# MCAN0_CFG_MCAN0_CFG register map
Vendor: Texas Instruments
Peripheral module from a debugger description file (folder AM263).
Registers are 32-bit, read-write, reset 0x0 unless marked. A register's access mark holds for its fields unless they carry their own. Offsets are as the file gives them; lines under a group give offsets from that group; [hi:lo] are bit positions; {n}, {i} and the like mark numbered series; 'fields as' and 'values as' point back to an identical list; <NAME> marks a mode.

## MCAN0_CFG_MCAN0_CFG
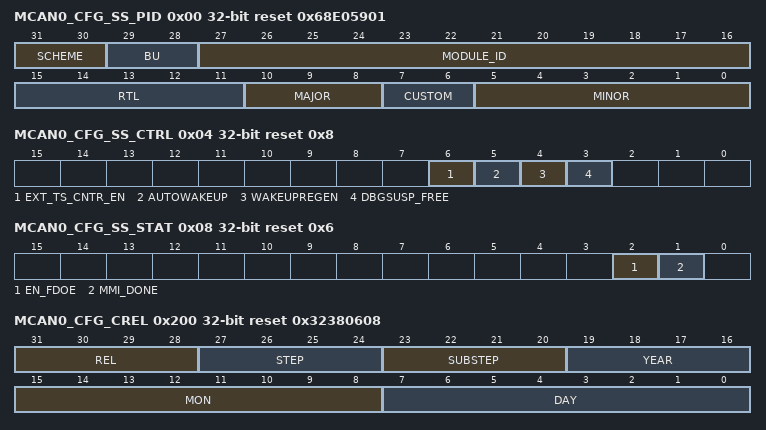
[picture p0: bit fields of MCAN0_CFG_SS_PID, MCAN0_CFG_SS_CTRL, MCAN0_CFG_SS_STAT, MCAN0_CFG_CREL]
0x00 MCAN0_CFG_SS_PID ro reset 0x68E05901
  [31:30] SCHEME — PID register scheme
  [29:28] BU — Business Unit: 10 = Processors
  [27:16] MODULE_ID
  [15:11] RTL — RTL revision. Will vary depending on release.
  [10:8] MAJOR — Major revision
  [7:6] CUSTOM
  [5:0] MINOR — Minor revision
0x04 MCAN0_CFG_SS_CTRL reset 0x8
  [6] EXT_TS_CNTR_EN — External TimeStamp Counter Enable
  [5] AUTOWAKEUP — Automatic Wakeup Enable
  [4] WAKEUPREGEN — Wakeup Request Enable
  [3] DBGSUSP_FREE — 0-Honor Debug Suspend, 1-Disregard debug suspend
0x08 MCAN0_CFG_SS_STAT ro reset 0x6
  [2] EN_FDOE — Reflects the value of mcanss_enable_fdoe configuration portx=mcanss_enable_fdoe
  [1] MMI_DONE — 0:Memory Initialization is in progress, 1:Memory Intialization Done
0x0C MCAN0_CFG_SS_ICS wo
  [0] ICS — This bit contains the External TimeStamp Counter Overflow Interrupt status. Write '1' to clear bits. (ICS - Interrupt Clear Shadow Register)
0x10 MCAN0_CFG_SS_IRS ro
  [0] IRS — External TimeStamp Counter Overflow Interrupt status. Read raw interrupt status. (IRS - Interrupt Raw Status Register)
0x14 MCAN0_CFG_SS_IECS wo
  [0] IECS — External TimeStamp Counter Overflow Interrupt. Write '1' to clear bits. (IECS - Interrupt Enable Clear Shadow Register)
0x18 MCAN0_CFG_SS_IE
  [0] IE — External TimeStamp Counter Overflow Interrupt. Write '1' to set interrupt enable. Read returns interrupt enable. (IE - Interrupt Enable Register)
0x1C MCAN0_CFG_SS_IES ro
  [0] IES — External TimeStamp Counter Overflow Interrupt. Read Enabled Interrupts. (IES - Interrupt Enable Status)
0x20 MCAN0_CFG_SS_EOI wo
  [7:0] EOI — Write with bit position of targeted interrupt. (E.g. Ext TS is bit 0).Upon write, level interrupt will clear and if unserviced interrupt counter > 1 will issue another pulse interrupt. Field values: ext_ts_eoi(0): EOI value for External TS interrupt mcan_0_eoi(1): EOI value for mcan[0] interrupt mcan_1_eoi(2): EOI value for mcan[1] interrupt(EOI - End Of Interrupt)
0x24 MCAN0_CFG_SS_EXT_TS_PS
  [23:0] PRESCALE — External Timestamp Prescaler reload value.External Timestamp count rate is host clock rate divided by this valuewith one exception: a value of 0 has the same effect as 1 .
0x28 MCAN0_CFG_SS_EXT_TS_USIC ro
  [4:0] EXT_TS_INTR_CNTR — Number of unserviced rollover interrupts. If >1 an EOI write will issue another pulse interrupt (EXT_TS_USIC - External TImeStamp Unserviced Interrupts Counter)
0x200 MCAN0_CFG_CREL ro reset 0x32380608
  [31:28] REL — Core Release
  [27:24] STEP — Step of Core Release
  [23:20] SUBSTEP — Sub-Step of Core Release
  [19:16] YEAR — Time Stamp Year
  [15:8] MON — Time Stamp Month
  [7:0] DAY — Time Stamp Day
0x204 MCAN0_CFG_ENDN ro reset 0x87654321
  [31:0] ETV — Endianess test value
0x208 MCAN0_CFG_CUST ro
  [31:0] CUST — Custom
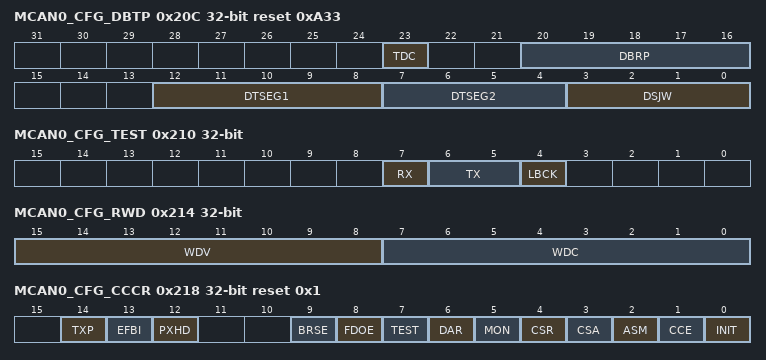
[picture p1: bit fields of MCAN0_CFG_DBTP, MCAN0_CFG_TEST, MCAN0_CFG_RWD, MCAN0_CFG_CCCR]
0x20C MCAN0_CFG_DBTP reset 0xA33
  [23] TDC — Transmitter Delay Compensation
  [20:16] DBRP — Data Baud Rate Prescaler
  [12:8] DTSEG1 — Data time segment before smaple point
  [7:4] DTSEG2 — Data time segment after sample point
  [3:0] DSJW — Data resynchronization Jump Width
0x210 MCAN0_CFG_TEST access per field
  [7] RX ro — Receive Pin
  [6:5] TX rw — Control of Transmit Pin
  [4] LBCK rw — Loop Back Mode
0x214 MCAN0_CFG_RWD access per field
  [15:8] WDV ro — Watchdog Value
  [7:0] WDC rw — Watchdog Counter Value
0x218 MCAN0_CFG_CCCR access per field reset 0x1
  [14] TXP rw — Transmit Pause
  [13] EFBI rw — Edge Filtering durign Bus Integration
  [12] PXHD rw — Protocol Exception Handling Disable
  [9] BRSE rw — Bit Rate Switch Enable
  [8] FDOE rw — FD Operation Enable
  [7] TEST rw — Test Mode enable
  [6] DAR rw — Disable Automatic Regransmission
  [5] MON rw — Bus Monitoring Mode
  [4] CSR rw — Clock Stop Request
  [3] CSA ro — Clock Stop Acknowledge
  [2] ASM rw — Restriced Operation Mode
  [1] CCE rw — Configuration Change Enable
  [0] INIT rw — Initialization
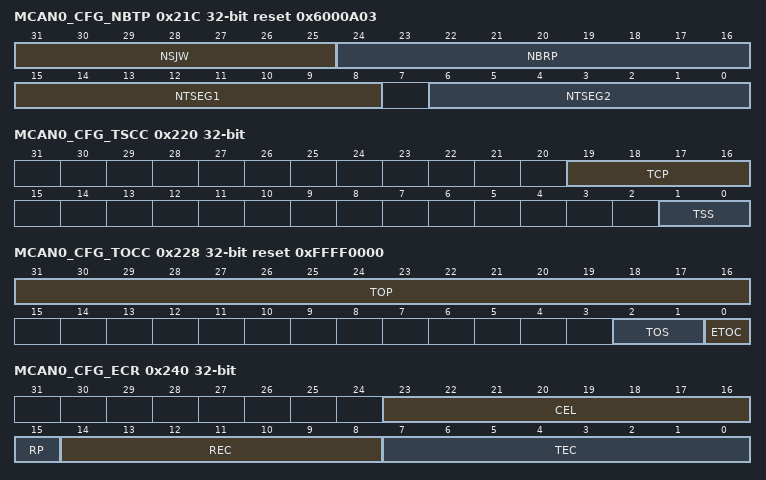
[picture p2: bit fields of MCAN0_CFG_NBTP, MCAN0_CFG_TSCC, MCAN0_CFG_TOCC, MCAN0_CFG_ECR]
0x21C MCAN0_CFG_NBTP reset 0x6000A03
  [31:25] NSJW — Nominal Resynchronization Jump Width
  [24:16] NBRP — Nominal Baud Rate Prescaler
  [15:8] NTSEG1 — Nominal Time segment before sample point
  [6:0] NTSEG2 — Nominal Time segment after sample point
0x220 MCAN0_CFG_TSCC
  [19:16] TCP — Timestamp Counter Prescaler
  [1:0] TSS — Timestamp Select
0x224 MCAN0_CFG_TSCV
  [15:0] TSC — Timestamp Counter
0x228 MCAN0_CFG_TOCC reset 0xFFFF0000
  [31:16] TOP — Timeout Period
  [2:1] TOS — Timeout Select
  [0] ETOC — Enable Timeout Counter
0x22C MCAN0_CFG_TOCV reset 0xFFFF
  [15:0] TOC — Timeout Counter
{0x230+4i} MCAN0_CFG_RES{i:02} access not given reset not defined (i=0..3)
0x240 MCAN0_CFG_ECR ro
  [23:16] CEL — CAN Error Logging
  [15] RP — Recieve Error Passive
  [14:8] REC — Recieve Error Counter
  [7:0] TEC — Transmit Error Counter
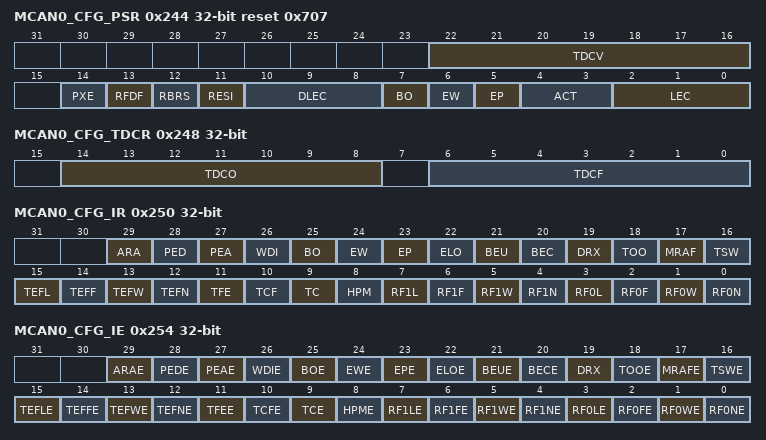
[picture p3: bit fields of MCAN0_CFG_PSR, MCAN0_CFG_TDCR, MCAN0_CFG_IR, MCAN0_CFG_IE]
0x244 MCAN0_CFG_PSR ro reset 0x707
  [22:16] TDCV — Transmitter Delay Compensation Value
  [14] PXE — Protocol Exception Event
  [13] RFDF — Recieved a CAN FD Message
  [12] RBRS — BRS flag of last recieved CAN FD Message
  [11] RESI — ESI flag of last recieved CAN FD Message
  [10:8] DLEC — Data Phase Last Error Code
  [7] BO — Bus_Off status
  [6] EW — Warning Status
  [5] EP — Error Passive
  [4:3] ACT — Activity
  [2:0] LEC — Last Error Code
0x248 MCAN0_CFG_TDCR
  [14:8] TDCO — Transmitter Delay Compensation Offset
  [6:0] TDCF — Transmitter Delay Compensation Filter Window Length
0x24C MCAN0_CFG_RES04 access not given reset not defined
0x250 MCAN0_CFG_IR
  [29] ARA — Access to Reserved Address
  [28] PED — Protocol Error in data Phase
  [27] PEA — Protocol Error in Arbitration Phase
  [26] WDI — Watchdog Interrupt
  [25] BO — Bus_Off Status
  [24] EW — Warning Status
  [23] EP — Error Passive
  [22] ELO — Error Logging Overflow
  [21] BEU — Bit Error Uncorrected
  [20] BEC — Bit Error Corrected
  [19] DRX — Message stored to Dedicated Rx Buffer
  [18] TOO — Timeout Occurred
  [17] MRAF — Message RAM Access Failure
  [16] TSW — Timestamp Wraparound
  [15] TEFL — Tx Event FIFO Element Lost
  [14] TEFF — Tx Event FIFO Full
  [13] TEFW — Tx Event FIFO Watermark Reached
  [12] TEFN — Tx Event FIFO New Entry
  [11] TFE — Tx FIFO Empty
  [10] TCF — Transmission Cancellation Finished
  [9] TC — Transmission Complete
  [8] HPM — High Priority Message
  [7] RF1L — Rx FIFO 1 Message Lost
  [6] RF1F — Rx FIFO 1 Full
  [5] RF1W — Rx FIFO 1 Watermark Reached
  [4] RF1N — Rx FIFO 1 New Message
  [3] RF0L — Rx FIFO 0 Message Lost
  [2] RF0F — Rx FIFO 0 Full
  [1] RF0W — Rx FIFO 0 Watermark Reached
  [0] RF0N — Rx FIFO 0 New Message
0x254 MCAN0_CFG_IE
  [29] ARAE — Accees to Reserve Address Interrupt Enable
  [28] PEDE — Protocol Error in Data Phase Interrupt Enable
  [27] PEAE — Protocol Error in Arbitration Phase Interrupt Enable
  [26] WDIE — Watchdog Interrupt Enable
  [25] BOE — Bus_Off Status Interrupt Enable
  [24] EWE — Warning Status Interrupt Enable
  [23] EPE — Error Passive Interrupt Enable
  [22] ELOE — Error Logging Overflow Interrupt Enable
  [21] BEUE — Bit Error Uncorrected Interrupt Enable
  [20] BECE — Bit Error Corrected Interrupt Enable
  [19] DRX — Message stored to Dedicated Rx Buffer Interrupt Enable
  [18] TOOE — Timeout Occurred Interrupt Enable
  [17] MRAFE — Message RAM Access Failure Interrupt Enable
  [16] TSWE — Timestamp Wraparound Interrupt Enable
  [15] TEFLE — Tx Event FIFO Event Lost Interrupt Enable
  [14] TEFFE — Tx Event FIFO Full Interrupt Enable
  [13] TEFWE — Tx Event FIFO Watermark Reached Interrupt enable
  [12] TEFNE — Tx Event FIFO New Entry Interrupt Enable
  [11] TFEE — Tx FIFO Empty Interrupt Enable
  [10] TCFE — Transmission Cancellation Finishied Interrupt Enable
  [9] TCE — Transmission Completed Interrupt Enable
  [8] HPME — High Priority message Interrupt Enable
  [7] RF1LE — rx FIFO 1 Message Lost Interrupt Enable
  [6] RF1FE — Rx FIFO 1 Full Interrupt Enable
  [5] RF1WE — Rx FIFO 1 Watermark Reached Interrupt Enable
  [4] RF1NE — Rx FIFO 1 New Message Interrupt Enable
  [3] RF0LE — Rx FIFO 0 Message Lost Interrupt Enable
  [2] RF0FE — Rx FIFO 0 Full Interrupt Enable
  [1] RF0WE — Rx FIFO 0 Watermark Reached Interrupt Enable
  [0] RF0NE — Rx FIFO 0 New Message Interrupt Enable
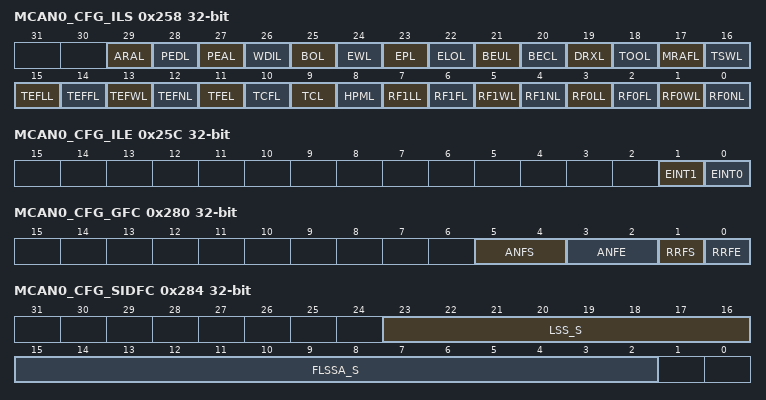
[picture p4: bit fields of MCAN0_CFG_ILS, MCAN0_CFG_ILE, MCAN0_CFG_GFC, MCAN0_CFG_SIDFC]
0x258 MCAN0_CFG_ILS
  [29] ARAL — Accees to Reserve Address Interrupt Line
  [28] PEDL — Protocol Error in Data Phase Interrupt Line
  [27] PEAL — Protocol Error in Arbitration Phase Interrupt Line
  [26] WDIL — Watchdog Interrupt Line
  [25] BOL — Bus_Off Status Interrupt Line
  [24] EWL — Warning Status Interrupt Line
  [23] EPL — Error Passive Interrupt Line
  [22] ELOL — Error Logging Overflow Interrupt Line
  [21] BEUL — Bit Error Uncorrected Interrupt Line
  [20] BECL — Bit Error Corrected Interrupt Line
  [19] DRXL — Message stored to Dedicated Rx Buffer Interrupt Line
  [18] TOOL — Timeout Occurred Interrupt Line
  [17] MRAFL — Message RAM Access Failure Interrupt Line
  [16] TSWL — Timestamp Wraparound Interrupt Line
  [15] TEFLL — Tx Event FIFO Event Lost Interrupt Line
  [14] TEFFL — Tx Event FIFO Full Interrupt Line
  [13] TEFWL — Tx Event FIFO Watermark Reached Interrupt Line
  [12] TEFNL — Tx Event FIFO New Entry Interrupt Line
  [11] TFEL — Tx FIFO Empty Interrupt Line
  [10] TCFL — Transmission Cancellation Finishied Interrupt Line
  [9] TCL — Transmission Completed Interrupt Line
  [8] HPML — High Priority message Interrupt Line
  [7] RF1LL — rx FIFO 1 Message Lost Interrupt Line
  [6] RF1FL — Rx FIFO 1 Full Interrupt Line
  [5] RF1WL — Rx FIFO 1 Watermark Reached Interrupt Line
  [4] RF1NL — Rx FIFO 1 New Message Interrupt Line
  [3] RF0LL — Rx FIFO 0 Message Lost Interrupt Line
  [2] RF0FL — Rx FIFO 0 Full Interrupt Line
  [1] RF0WL — Rx FIFO 0 Watermark Reached Interrupt Line
  [0] RF0NL — Rx FIFO 0 New Message Interrupt Line
0x25C MCAN0_CFG_ILE
  [1] EINT1 — Enable Interrupt Line 1
  [0] EINT0 — Enable Interrupt Line 0
{0x24C+4i} MCAN0_CFG_RES{i:02} access not given reset not defined (i=5..12)
0x280 MCAN0_CFG_GFC
  [5:4] ANFS — Accept Non-matching Frames Standard
  [3:2] ANFE — Accept Non-matching Frames Extended
  [1] RRFS — reject Remote Frames Standard
  [0] RRFE — reject Remote Frames Extended
0x284 MCAN0_CFG_SIDFC
  [23:16] LSS_S — List Size Standard
  [15:2] FLSSA_S — Filter List Standard Start Address
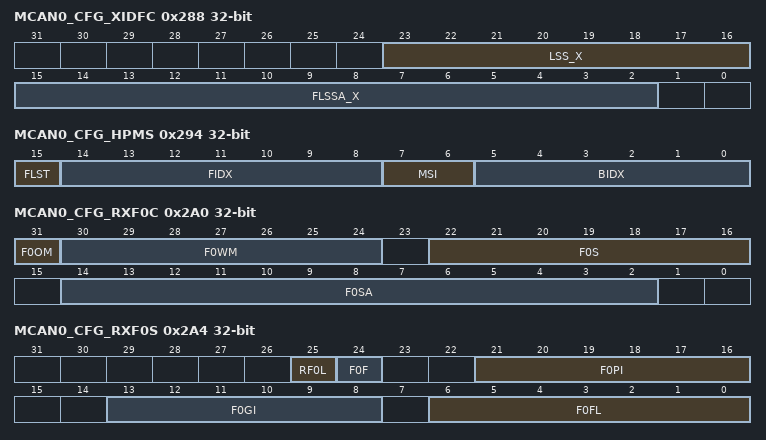
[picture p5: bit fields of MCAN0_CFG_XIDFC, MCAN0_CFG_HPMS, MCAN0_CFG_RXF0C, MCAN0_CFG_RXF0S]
0x288 MCAN0_CFG_XIDFC
  [23:16] LSS_X — List Size Standard
  [15:2] FLSSA_X — Filter List Standard Start Address
0x28C MCAN0_CFG_RES13 access not given reset not defined
0x290 MCAN0_CFG_XIDAM reset 0x1FFFFFFF
  [28:0] EIDM — Extended ID Mask
0x294 MCAN0_CFG_HPMS ro
  [15] FLST — Filter List
  [14:8] FIDX — Filter Index
  [7:6] MSI — Message Storeage Indicator
  [5:0] BIDX — Buffer Index
0x298 MCAN0_CFG_NDAT1
  [31:0] ND0_31 — New Data 0-31
0x29C MCAN0_CFG_NDAT2
  [31:0] ND32_63 — New Data 32-63
0x2A0 MCAN0_CFG_RXF0C
  [31] F0OM — Rx FIFO 0 Operation Mode
  [30:24] F0WM — Rx FIFO 0 Watermark
  [22:16] F0S — Rx FIFO 0 Size
  [14:2] F0SA — Rx FIFO 0 Start Address
0x2A4 MCAN0_CFG_RXF0S ro
  [25] RF0L — Rx FIFO 0 Message Lost
  [24] F0F — Rx FIFO 0 Full
  [21:16] F0PI — Rx FIFO 0 Put Index
  [13:8] F0GI — Rx FIFO 0 Get Index
  [6:0] F0FL — Rx FIFO 0 Fill Level
0x2A8 MCAN0_CFG_RXF0A
  [5:0] F0AI — Rx FIFO 0 Acknowledge Index
0x2AC MCAN0_CFG_RXBC
  [15:2] RBSA — Rx Buffer Start Address
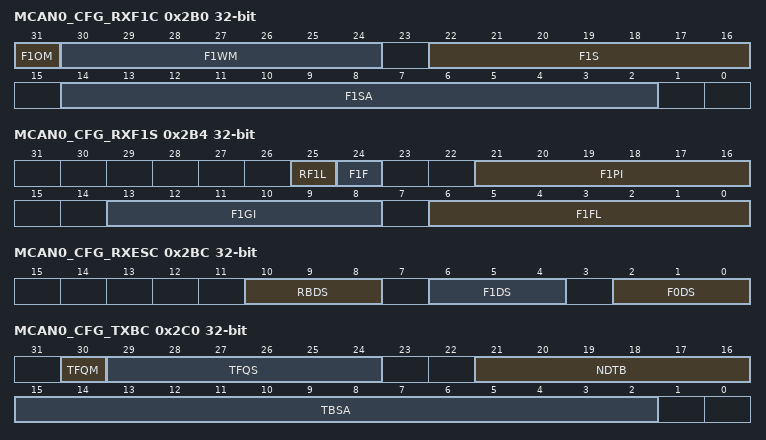
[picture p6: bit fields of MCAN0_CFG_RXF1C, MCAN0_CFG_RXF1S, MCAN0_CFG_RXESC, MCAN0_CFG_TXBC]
0x2B0 MCAN0_CFG_RXF1C
  [31] F1OM — Rx FIFO 0 Operation Mode
  [30:24] F1WM — Rx FIFO 0 Watermark
  [22:16] F1S — Rx FIFO 0 Size
  [14:2] F1SA — Rx FIFO 0 Start Address
0x2B4 MCAN0_CFG_RXF1S ro
  [25] RF1L — Rx FIFO 0 Message Lost
  [24] F1F — Rx FIFO 0 Full
  [21:16] F1PI — Rx FIFO 0 Put Index
  [13:8] F1GI — Rx FIFO 0 Get Index
  [6:0] F1FL — Rx FIFO 0 Fill Level
0x2B8 MCAN0_CFG_RXF1A
  [5:0] F1AI — Rx FIFO 0 Acknowledge Index
0x2BC MCAN0_CFG_RXESC
  [10:8] RBDS — Rx Buffer data Field Size
  [6:4] F1DS — Rx FIFO 1 Data Field Size
  [2:0] F0DS — Rx FIFO 0 Data Field Size
0x2C0 MCAN0_CFG_TXBC ro
  [30] TFQM — Tx FIFO/Queue Mode
  [29:24] TFQS — Transmit FIFO/Queue Size
  [21:16] NDTB — Number of Dedicated Transmit Buffers
  [15:2] TBSA — Tx Buffers Start Address
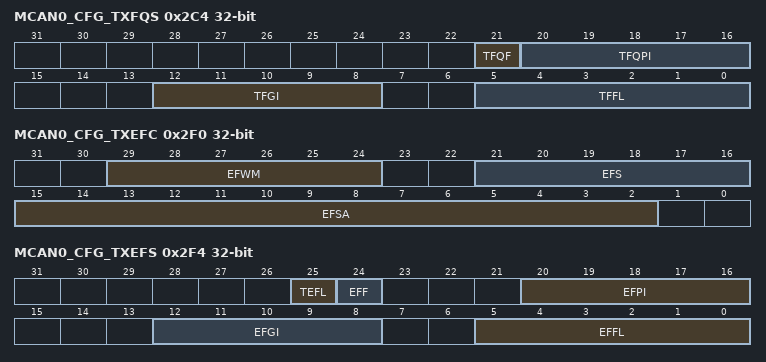
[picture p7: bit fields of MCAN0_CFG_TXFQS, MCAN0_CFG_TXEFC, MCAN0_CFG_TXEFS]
0x2C4 MCAN0_CFG_TXFQS ro
  [21] TFQF — Tx FIFO/Queue Full
  [20:16] TFQPI — Tx FIFO/Queue Put Index
  [12:8] TFGI — Tx Queue Get Index
  [5:0] TFFL — Tx FIFO Free Level
0x2C8 MCAN0_CFG_TXESC
  [2:0] TBDS — Tx Buffer Data Field Size
0x2CC MCAN0_CFG_TXBRP ro
  [31:0] TRP — Transmission Request Pending
0x2D0 MCAN0_CFG_TXBAR access not given
  [31:0] AR — Add request (access RW W0TOCLR)
0x2D4 MCAN0_CFG_TXBCR access not given
  [31:0] CR — Cancellation Request (access RW W0TOCLR)
0x2D8 MCAN0_CFG_TXBTO ro
  [31:0] TO — Transmission Occurred
0x2DC MCAN0_CFG_TXBCF ro
  [31:0] CF — Cancellation Finished
0x2E0 MCAN0_CFG_TXBTIE
  [31:0] TIE — Transmission Interrupt Enable
0x2E4 MCAN0_CFG_TXBCIE
  [31:0] CFIE — Cancellation Finished Interrupt Enable
0x2E8 MCAN0_CFG_RES14 access not given reset not defined
0x2EC MCAN0_CFG_RES15 access not given reset not defined
0x2F0 MCAN0_CFG_TXEFC
  [29:24] EFWM — Event FIFO Watermark
  [21:16] EFS — Event FIFO Size
  [15:2] EFSA — Event FIFO Start Address
0x2F4 MCAN0_CFG_TXEFS ro
  [25] TEFL — Tx Event FIFO Element Lost
  [24] EFF — Event FIFO Full
  [20:16] EFPI — Event FIFO Put Index
  [12:8] EFGI — Event FIFO Get Index
  [5:0] EFFL — Event FIFO FIll Level
0x2F8 MCAN0_CFG_TXEFA ro
  [4:0] EFAI — Event FIFO Acknowledge Index
0x2FC MCAN0_CFG_RES16 access not given reset not defined
